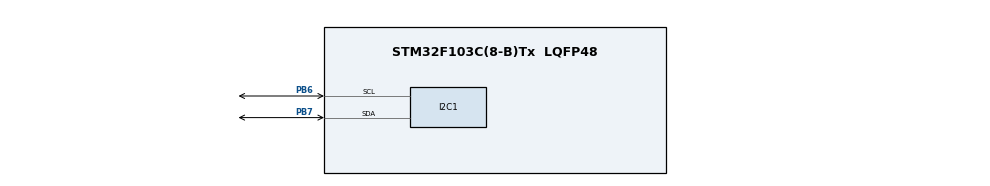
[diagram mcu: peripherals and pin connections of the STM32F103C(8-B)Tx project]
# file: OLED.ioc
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Mcu.Family=STM32F1
Mcu.Name=STM32F103C(8-B)Tx
Mcu.Package=LQFP48
NVIC.PriorityGroup=NVIC_PRIORITYGROUP_4
PA13.Mode=Serial_Wire
PA13.Signal=SYS_JTMS-SWDIO
PA14.Mode=Serial_Wire
PA14.Signal=SYS_JTCK-SWCLK
PB6.Mode=I2C
PB6.Signal=I2C1_SCL
PB7.Mode=I2C
PB7.Signal=I2C1_SDA
PD0-OSC_IN.Mode=HSE-External-Oscillator
PD0-OSC_IN.Signal=RCC_OSC_IN
PD1-OSC_OUT.Mode=HSE-External-Oscillator
PD1-OSC_OUT.Signal=RCC_OSC_OUT
ProjectManager.HeapSize=0x200
ProjectManager.StackSize=0x400
ProjectManager.TargetToolchain=STM32CubeIDE
RCC.APB1Freq_Value=8000000
RCC.APB2Freq_Value=8000000
board=custom

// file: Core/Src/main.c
/* USER CODE BEGIN Header */
/**
  ******************************************************************************
  * @file           : main.c
  * @brief          : Main program body
  ******************************************************************************
  * @attention
  *
  * Copyright (c) 2026 STMicroelectronics.
  * All rights reserved.
  *
  * This software is licensed under terms that can be found in the LICENSE file
  * in the root directory of this software component.
  * If no LICENSE file comes with this software, it is provided AS-IS.
  *
  ******************************************************************************
  */
/* USER CODE END Header */
#include "main.h"
#include "i2c.h"
#include "gpio.h"
#include "ssd1306.h"

void SystemClock_Config(void);

int main(void)
{

  /* USER CODE BEGIN 1 */

	 uint32_t counter = 0;
	    char text[32];

	    /* USER CODE END 1 */

	    /* STM32 HAL 初始化 */
	    HAL_Init();

	    /* 系统时钟初始化 */
	    SystemClock_Config();

	    /* 外设初始化 */
	    MX_GPIO_Init();
	    MX_I2C1_Init();

	    /* USER CODE BEGIN 2 */

	    /* 初始化 OLED */
	    ssd1306_Init(&hi2c1);

  /* USER CODE END 1 */

  /* MCU Configuration--------------------------------------------------------*/

  /* Reset of all peripherals, Initializes the Flash interface and the Systick. */
  HAL_Init();

  /* USER CODE BEGIN Init */

  /* USER CODE END Init */

  /* Configure the system clock */
  SystemClock_Config();

  /* USER CODE BEGIN SysInit */

  /* USER CODE END SysInit */

  /* Initialize all configured peripherals */
  MX_GPIO_Init();
  MX_I2C1_Init();
  /* USER CODE BEGIN 2 */

  /* USER CODE END 2 */

  /* Infinite loop */
  while (1)
  {

      ssd1306_Fill(Black);
      ssd1306_SetCursor(0, 0);
      ssd1306_WriteString("Hello World", Font_7x10, White);

      snprintf(text, sizeof(text), "Count: %lu", (unsigned long)counter);

      ssd1306_SetCursor(0, 20);
      ssd1306_WriteString(text, Font_7x10, White);

      ssd1306_UpdateScreen(&hi2c1);

      counter++;

      HAL_Delay(1000);

  }
}

void SystemClock_Config(void)
{
  RCC_OscInitTypeDef RCC_OscInitStruct = {0};
  RCC_ClkInitTypeDef RCC_ClkInitStruct = {0};

  /** Initializes the RCC Oscillators according to the specified parameters
  * in the RCC_OscInitTypeDef structure.
  */
  RCC_OscInitStruct.OscillatorType = RCC_OSCILLATORTYPE_HSI;
  RCC_OscInitStruct.HSIState = RCC_HSI_ON;
  RCC_OscInitStruct.HSICalibrationValue = RCC_HSICALIBRATION_DEFAULT;
  RCC_OscInitStruct.PLL.PLLState = RCC_PLL_NONE;
  if (HAL_RCC_OscConfig(&RCC_OscInitStruct) != HAL_OK)
  {
    Error_Handler();
  }

  /** Initializes the CPU, AHB and APB buses clocks
  */
  RCC_ClkInitStruct.ClockType = RCC_CLOCKTYPE_HCLK|RCC_CLOCKTYPE_SYSCLK
                              |RCC_CLOCKTYPE_PCLK1|RCC_CLOCKTYPE_PCLK2;
  RCC_ClkInitStruct.SYSCLKSource = RCC_SYSCLKSOURCE_HSI;
  RCC_ClkInitStruct.AHBCLKDivider = RCC_SYSCLK_DIV1;
  RCC_ClkInitStruct.APB1CLKDivider = RCC_HCLK_DIV1;
  RCC_ClkInitStruct.APB2CLKDivider = RCC_HCLK_DIV1;

  if (HAL_RCC_ClockConfig(&RCC_ClkInitStruct, FLASH_LATENCY_0) != HAL_OK)
  {
    Error_Handler();
  }
}

void Error_Handler(void)
{
  __disable_irq();
  while (1)
  {
  }
}
